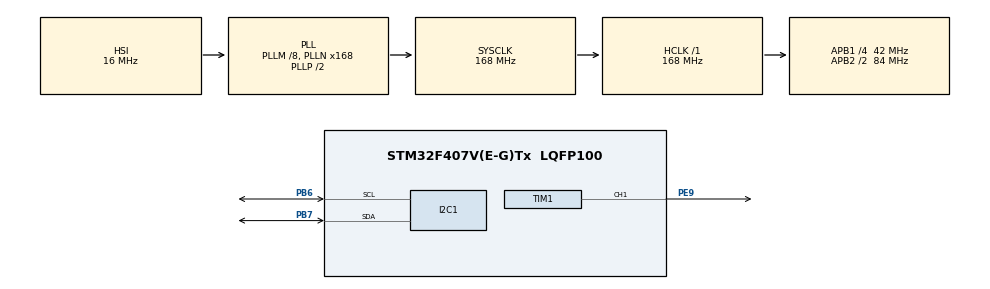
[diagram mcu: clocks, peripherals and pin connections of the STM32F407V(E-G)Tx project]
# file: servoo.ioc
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Mcu.Family=STM32F4
Mcu.Name=STM32F407V(E-G)Tx
Mcu.Package=LQFP100
NVIC.PriorityGroup=NVIC_PRIORITYGROUP_0
PB6.Mode=I2C
PB6.Signal=I2C1_SCL
PB7.Mode=I2C
PB7.Signal=I2C1_SDA
PE9.Signal=S_TIM1_CH1
ProjectManager.HeapSize=0x200
ProjectManager.StackSize=0x400
ProjectManager.TargetToolchain=STM32CubeIDE
RCC.48MHZClocksFreq_Value=48000000
RCC.AHBFreq_Value=168000000
RCC.APB1CLKDivider=RCC_HCLK_DIV4
RCC.APB1Freq_Value=42000000
RCC.APB1TimFreq_Value=84000000
RCC.APB2CLKDivider=RCC_HCLK_DIV2
RCC.APB2Freq_Value=84000000
RCC.APB2TimFreq_Value=168000000
RCC.CortexFreq_Value=168000000
RCC.HCLKFreq_Value=168000000
RCC.HSE_VALUE=8000000
RCC.HSI_VALUE=16000000
RCC.LSE_VALUE=32768
RCC.PLLM=8
RCC.PLLN=168
RCC.PLLQ=7
RCC.SYSCLKFreq_VALUE=168000000
RCC.SYSCLKSource=RCC_SYSCLKSOURCE_PLLCLK
RCC.VCOOutputFreq_Value=336000000
SH.S_TIM1_CH1.0=TIM1_CH1,PWM Generation1 CH1
TIM1.Channel-PWM\ Generation1\ CH1=TIM_CHANNEL_1
TIM1.Period=19999
TIM1.Prescaler=83
VP_TIM1_VS_ClockSourceINT.Mode=Internal
board=STM32F407G-DISC1

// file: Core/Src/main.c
/* USER CODE BEGIN Header */
/**
  ******************************************************************************
  * @file           : main.c
  * @brief          : Main program body
  ******************************************************************************
  * @attention
  *
  * Copyright (c) 2024 STMicroelectronics.
  * All rights reserved.
  *
  * This software is licensed under terms that can be found in the LICENSE file
  * in the root directory of this software component.
  * If no LICENSE file comes with this software, it is provided AS-IS.
  *
  ******************************************************************************
  */
/* USER CODE END Header */
#include "main.h"
#include "i2c-lcd.h"

I2C_HandleTypeDef hi2c1;

TIM_HandleTypeDef htim1;

/* USER CODE BEGIN PV */
char lcd_buffer[16]; // To store the speed display string
uint32_t start_time, end_time;
uint32_t prev_time = 0;
uint32_t current_time = 0;
float servo_speed_up = 0;  // Speed during upward motion
float servo_speed_down = 0;  // Speed during downward motion
int total_range = 5200 - 1000; // Différence totale de position

int delay_time = 100; // Délai ajusté (plus grand pour plus de précision)
/* USER CODE END PV */

void SystemClock_Config(void);
static void MX_GPIO_Init(void);
static void MX_TIM1_Init(void);
static void MX_I2C1_Init(void);

int main(void)
{

  /* MCU Configuration--------------------------------------------------------*/

  /* Reset of all peripherals, Initializes the Flash interface and the Systick. */
  HAL_Init();

  /* Configure the system clock */
  SystemClock_Config();

  /* Initialize all configured peripherals */
  MX_GPIO_Init();
  MX_TIM1_Init();
  MX_I2C1_Init();
  /* USER CODE BEGIN 2 */
  HAL_TIM_PWM_Start(&htim1, TIM_CHANNEL_1);
  /* USER CODE END 2 */
  lcd_init();  // Initialize the LCD

  	  lcd_put_cur(0, 0);
  	  lcd_send_string("Servo Speed:");
  	  HAL_Delay(200);
  	 lcd_clear(); // Clear the display
  /* Infinite loop */
  while (1)
  {
	  // Mouvement du servo dans la direction ascendante
	      start_time = HAL_GetTick();  // Temps de départ
	      for(int x = 1000; x < 5200; x += 50)
	      {
	          __HAL_TIM_SET_COMPARE(&htim1, TIM_CHANNEL_1, x);
	          HAL_Delay(delay_time);  // Délai pour simuler le balayage
	      }
	      end_time = HAL_GetTick();  // Temps à la fin du parcours ascendant

	      // Calcul du temps total pour la montée
	      uint32_t time_up = end_time - start_time;  // Temps en ms
	      // Calcul de la vitesse moyenne (angle/durée en ms)
	      servo_speed_up = (float)total_range / time_up * 1000; // Convertir en unité "position/s"

	      // Affichage de la vitesse de montée sur le LCD
	      lcd_put_cur(0, 0); // Première ligne
	      sprintf(lcd_buffer, "Up: %.2f", servo_speed_up);
	      lcd_send_string(lcd_buffer);

	      HAL_Delay(2000); // Laisser le temps d'afficher

	      // Mouvement du servo dans la direction descendante
	      start_time = HAL_GetTick();  // Temps de départ
	      for(int x = 5200; x > 1000; x -= 20)
	      {
	          __HAL_TIM_SET_COMPARE(&htim1, TIM_CHANNEL_1, x);
	          HAL_Delay(delay_time);  // Délai pour simuler le balayage
	      }
	      end_time = HAL_GetTick();  // Temps à la fin du parcours descendant

	      // Calcul du temps total pour la descente
	      uint32_t time_down = end_time - start_time;  // Temps en ms
	      // Calcul de la vitesse moyenne (angle/durée en ms)
	      servo_speed_down = (float)total_range / time_down * 1000; // Convertir en unité "position/s"

	      // Affichage de la vitesse de descente sur le LCD
	      lcd_put_cur(1, 0); // Deuxième ligne
	      sprintf(lcd_buffer, "Down: %.2f", servo_speed_down);
	      lcd_send_string(lcd_buffer);

	      HAL_Delay(2000); // Laisser le temps d'afficher
	  }
}

void SystemClock_Config(void)
{
  RCC_OscInitTypeDef RCC_OscInitStruct = {0};
  RCC_ClkInitTypeDef RCC_ClkInitStruct = {0};

  /** Configure the main internal regulator output voltage
  */
  __HAL_RCC_PWR_CLK_ENABLE();
  __HAL_PWR_VOLTAGESCALING_CONFIG(PWR_REGULATOR_VOLTAGE_SCALE1);

  /** Initializes the RCC Oscillators according to the specified parameters
  * in the RCC_OscInitTypeDef structure.
  */
  RCC_OscInitStruct.OscillatorType = RCC_OSCILLATORTYPE_HSI;
  RCC_OscInitStruct.HSIState = RCC_HSI_ON;
  RCC_OscInitStruct.HSICalibrationValue = RCC_HSICALIBRATION_DEFAULT;
  RCC_OscInitStruct.PLL.PLLState = RCC_PLL_ON;
  RCC_OscInitStruct.PLL.PLLSource = RCC_PLLSOURCE_HSI;
  RCC_OscInitStruct.PLL.PLLM = 8;
  RCC_OscInitStruct.PLL.PLLN = 168;
  RCC_OscInitStruct.PLL.PLLP = RCC_PLLP_DIV2;
  RCC_OscInitStruct.PLL.PLLQ = 7;
  if (HAL_RCC_OscConfig(&RCC_OscInitStruct) != HAL_OK)
  {
    Error_Handler();
  }

  /** Initializes the CPU, AHB and APB buses clocks
  */
  RCC_ClkInitStruct.ClockType = RCC_CLOCKTYPE_HCLK|RCC_CLOCKTYPE_SYSCLK
                              |RCC_CLOCKTYPE_PCLK1|RCC_CLOCKTYPE_PCLK2;
  RCC_ClkInitStruct.SYSCLKSource = RCC_SYSCLKSOURCE_PLLCLK;
  RCC_ClkInitStruct.AHBCLKDivider = RCC_SYSCLK_DIV1;
  RCC_ClkInitStruct.APB1CLKDivider = RCC_HCLK_DIV4;
  RCC_ClkInitStruct.APB2CLKDivider = RCC_HCLK_DIV2;

  if (HAL_RCC_ClockConfig(&RCC_ClkInitStruct, FLASH_LATENCY_5) != HAL_OK)
  {
    Error_Handler();
  }
}

static void MX_I2C1_Init(void)
{

  hi2c1.Instance = I2C1;
  hi2c1.Init.ClockSpeed = 100000;
  hi2c1.Init.DutyCycle = I2C_DUTYCYCLE_2;
  hi2c1.Init.OwnAddress1 = 0;
  hi2c1.Init.AddressingMode = I2C_ADDRESSINGMODE_7BIT;
  hi2c1.Init.DualAddressMode = I2C_DUALADDRESS_DISABLE;
  hi2c1.Init.OwnAddress2 = 0;
  hi2c1.Init.GeneralCallMode = I2C_GENERALCALL_DISABLE;
  hi2c1.Init.NoStretchMode = I2C_NOSTRETCH_DISABLE;
  if (HAL_I2C_Init(&hi2c1) != HAL_OK)
  {
    Error_Handler();
  }

}

static void MX_TIM1_Init(void)
{

  TIM_ClockConfigTypeDef sClockSourceConfig = {0};
  TIM_MasterConfigTypeDef sMasterConfig = {0};
  TIM_OC_InitTypeDef sConfigOC = {0};
  TIM_BreakDeadTimeConfigTypeDef sBreakDeadTimeConfig = {0};

  htim1.Instance = TIM1;
  htim1.Init.Prescaler = 83;
  htim1.Init.CounterMode = TIM_COUNTERMODE_UP;
  htim1.Init.Period = 19999;
  htim1.Init.ClockDivision = TIM_CLOCKDIVISION_DIV1;
  htim1.Init.RepetitionCounter = 0;
  htim1.Init.AutoReloadPreload = TIM_AUTORELOAD_PRELOAD_DISABLE;
  if (HAL_TIM_Base_Init(&htim1) != HAL_OK)
  {
    Error_Handler();
  }
  sClockSourceConfig.ClockSource = TIM_CLOCKSOURCE_INTERNAL;
  if (HAL_TIM_ConfigClockSource(&htim1, &sClockSourceConfig) != HAL_OK)
  {
    Error_Handler();
  }
  if (HAL_TIM_PWM_Init(&htim1) != HAL_OK)
  {
    Error_Handler();
  }
  sMasterConfig.MasterOutputTrigger = TIM_TRGO_RESET;
  sMasterConfig.MasterSlaveMode = TIM_MASTERSLAVEMODE_DISABLE;
  if (HAL_TIMEx_MasterConfigSynchronization(&htim1, &sMasterConfig) != HAL_OK)
  {
    Error_Handler();
  }
  sConfigOC.OCMode = TIM_OCMODE_PWM1;
  sConfigOC.Pulse = 0;
  sConfigOC.OCPolarity = TIM_OCPOLARITY_HIGH;
  sConfigOC.OCNPolarity = TIM_OCNPOLARITY_HIGH;
  sConfigOC.OCFastMode = TIM_OCFAST_DISABLE;
  sConfigOC.OCIdleState = TIM_OCIDLESTATE_RESET;
  sConfigOC.OCNIdleState = TIM_OCNIDLESTATE_RESET;
  if (HAL_TIM_PWM_ConfigChannel(&htim1, &sConfigOC, TIM_CHANNEL_1) != HAL_OK)
  {
    Error_Handler();
  }
  sBreakDeadTimeConfig.OffStateRunMode = TIM_OSSR_DISABLE;
  sBreakDeadTimeConfig.OffStateIDLEMode = TIM_OSSI_DISABLE;
  sBreakDeadTimeConfig.LockLevel = TIM_LOCKLEVEL_OFF;
  sBreakDeadTimeConfig.DeadTime = 0;
  sBreakDeadTimeConfig.BreakState = TIM_BREAK_DISABLE;
  sBreakDeadTimeConfig.BreakPolarity = TIM_BREAKPOLARITY_HIGH;
  sBreakDeadTimeConfig.AutomaticOutput = TIM_AUTOMATICOUTPUT_DISABLE;
  if (HAL_TIMEx_ConfigBreakDeadTime(&htim1, &sBreakDeadTimeConfig) != HAL_OK)
  {
    Error_Handler();
  }
  HAL_TIM_MspPostInit(&htim1);

}

static void MX_GPIO_Init(void)
{

  /* GPIO Ports Clock Enable */
  __HAL_RCC_GPIOE_CLK_ENABLE();
  __HAL_RCC_GPIOB_CLK_ENABLE();

}

void Error_Handler(void)
{
  __disable_irq();
  while (1)
  {
  }
}
